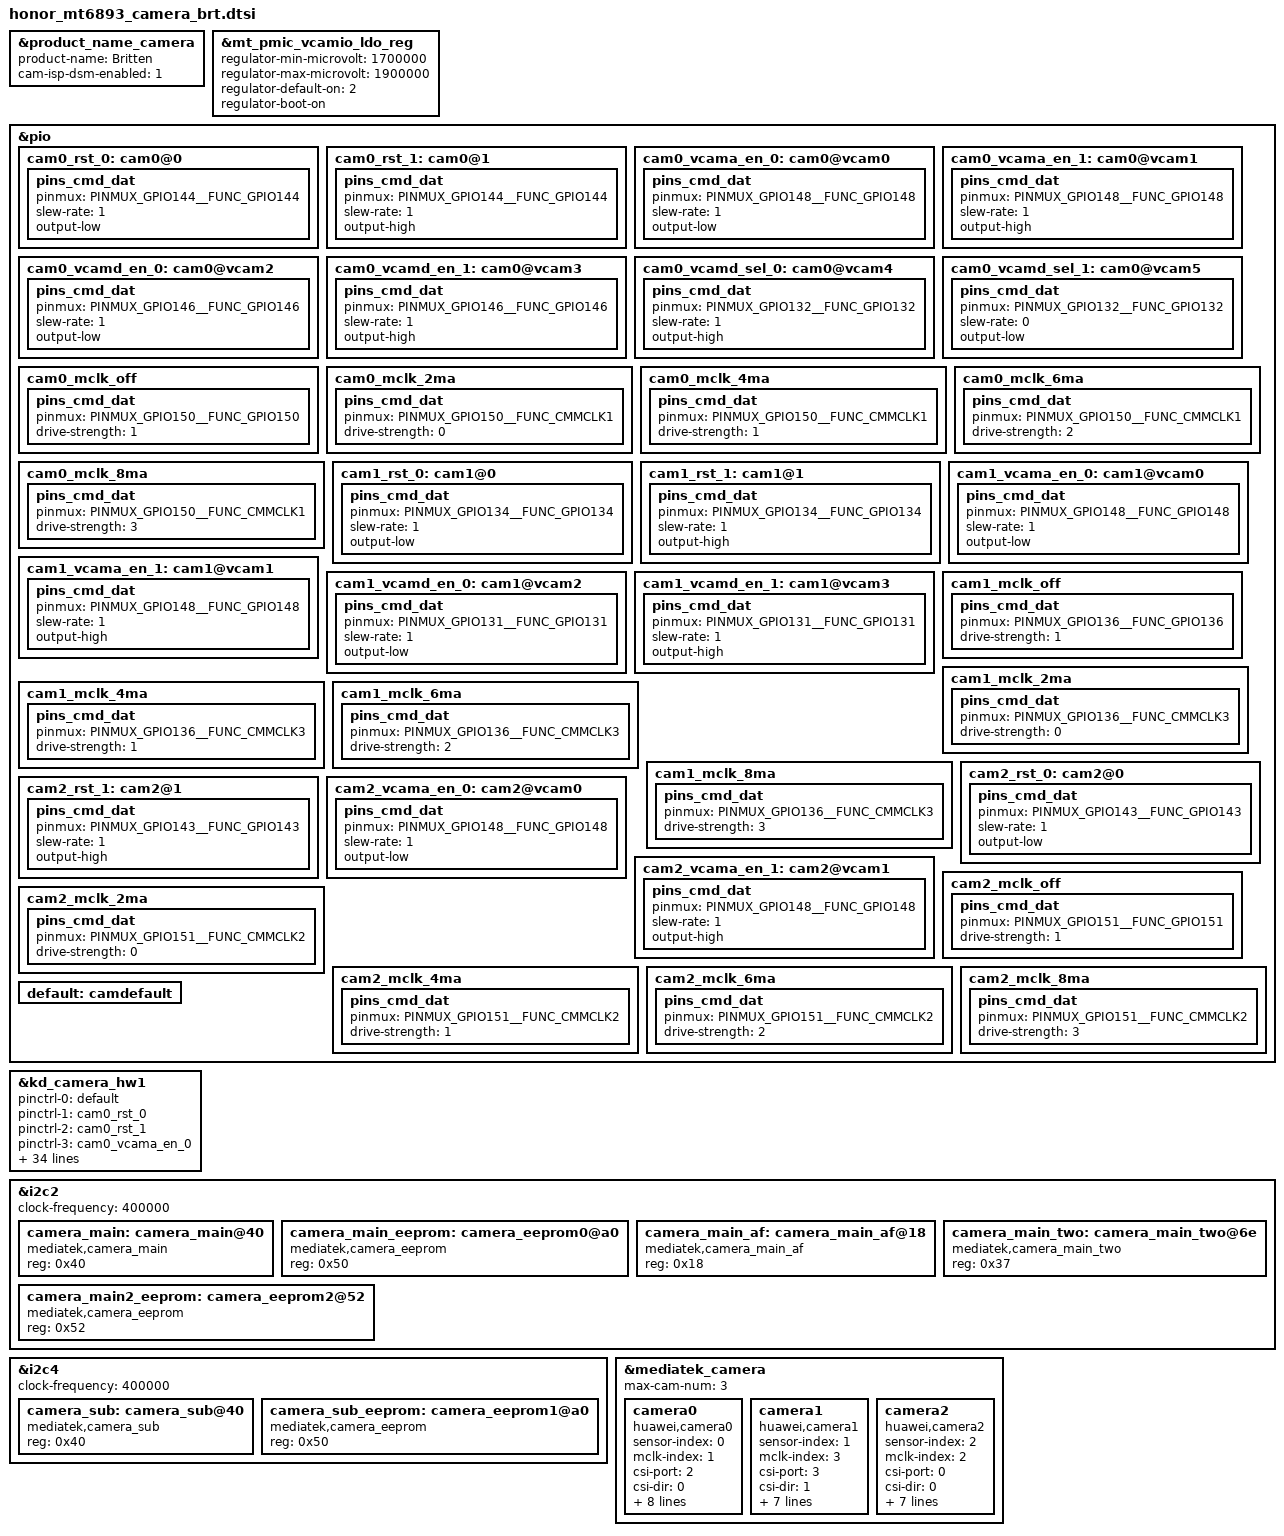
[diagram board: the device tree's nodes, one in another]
/*
 * hihonor_mt6893_camera_brt
 *
 * Copyright (c) 2021-2021 Hihonor Technologies Co., Ltd.
 *
 * hihonor_mt6893_camera_brt
 *
 * This software is licensed under the terms of the GNU General Public
 * License version 2, as published by the Free Software Foundation, and
 * may be copied, distributed, and modified under those terms.
 *
 * This program is distributed in the hope that it will be useful,
 * but WITHOUT ANY WARRANTY; without even the implied warranty of
 * MERCHANTABILITY or FITNESS FOR A PARTICULAR PURPOSE.  See the
 * GNU General Public License for more details.
 *
 */

&product_name_camera {
	product-name = "Britten";
	cam-isp-dsm-enabled = <1>;
};

&mt_pmic_vcamio_ldo_reg {
	regulator-min-microvolt = <1700000>;
	regulator-max-microvolt = <1900000>;
	regulator-default-on = <2>; /* 0:skip, 1: off, 2:on */
	regulator-boot-on;
};

/* CAMERA GPIO standardization */
&pio {
	/* Main Cam: cam0 GPIOs begin */
	cam0_rst_0: cam0@0 {
		pins_cmd_dat {
			pinmux = <PINMUX_GPIO144__FUNC_GPIO144>;
			slew-rate = <1>;
			output-low;
		};
	};
	cam0_rst_1: cam0@1 {
		pins_cmd_dat {
			pinmux = <PINMUX_GPIO144__FUNC_GPIO144>;
			slew-rate = <1>;
			output-high;
		};
	};
	cam0_vcama_en_0: cam0@vcam0 {
		pins_cmd_dat {
			pinmux = <PINMUX_GPIO148__FUNC_GPIO148>;
			slew-rate = <1>;
			output-low;
		};
	};
	cam0_vcama_en_1: cam0@vcam1 {
		pins_cmd_dat {
			pinmux = <PINMUX_GPIO148__FUNC_GPIO148>;
			slew-rate = <1>;
			output-high;
		};
	};
	cam0_vcamd_en_0: cam0@vcam2 {
		pins_cmd_dat {
			pinmux = <PINMUX_GPIO146__FUNC_GPIO146>;
			slew-rate = <1>;
			output-low;
		};
	};
	cam0_vcamd_en_1: cam0@vcam3 {
		pins_cmd_dat {
			pinmux = <PINMUX_GPIO146__FUNC_GPIO146>;
			slew-rate = <1>;
			output-high;
		};
	};
	/* sel 0, output 1.2V*/
	cam0_vcamd_sel_0: cam0@vcam4 {
		pins_cmd_dat {
			pinmux = <PINMUX_GPIO132__FUNC_GPIO132>;
			slew-rate = <1>;
			output-high;
		};
	};
	/* sel 1, output 1.1V*/
	cam0_vcamd_sel_1: cam0@vcam5 {
		pins_cmd_dat {
			pinmux = <PINMUX_GPIO132__FUNC_GPIO132>;
			slew-rate = <0>;
			output-low;
		};
	};
	cam0_mclk_off: cam0_mclk_off {
		pins_cmd_dat {
			pinmux = <PINMUX_GPIO150__FUNC_GPIO150>;
			drive-strength = <1>;
		};
	};
	cam0_mclk_2ma: cam0_mclk_2ma {
		pins_cmd_dat {
			pinmux = <PINMUX_GPIO150__FUNC_CMMCLK1>;
			drive-strength = <0>;
		};
	};
	cam0_mclk_4ma: cam0_mclk_4ma {
		pins_cmd_dat {
			pinmux = <PINMUX_GPIO150__FUNC_CMMCLK1>;
			drive-strength = <1>;
		};
	};
	cam0_mclk_6ma: cam0_mclk_6ma {
		pins_cmd_dat {
			pinmux = <PINMUX_GPIO150__FUNC_CMMCLK1>;
			drive-strength = <2>;
		};
	};
	cam0_mclk_8ma: cam0_mclk_8ma {
		pins_cmd_dat {
			pinmux = <PINMUX_GPIO150__FUNC_CMMCLK1>;
			drive-strength = <3>;
		};
	};
	/* Main Cam: cam0 GPIOs end */

	/* Sub(front) Cam: cam1 GPIOs begin */
	cam1_rst_0: cam1@0 {
		pins_cmd_dat {
			pinmux = <PINMUX_GPIO134__FUNC_GPIO134>;
			slew-rate = <1>;
			output-low;
		};
	};
	cam1_rst_1: cam1@1 {
		pins_cmd_dat {
			pinmux = <PINMUX_GPIO134__FUNC_GPIO134>;
			slew-rate = <1>;
			output-high;
		};
	};
   	cam1_vcama_en_0: cam1@vcam0 {
		pins_cmd_dat {
			pinmux = <PINMUX_GPIO148__FUNC_GPIO148>;
			slew-rate = <1>;
			output-low;
		};
	};
	cam1_vcama_en_1: cam1@vcam1 {
		pins_cmd_dat {
			pinmux = <PINMUX_GPIO148__FUNC_GPIO148>;
			slew-rate = <1>;
			output-high;
		};
	};
	cam1_vcamd_en_0: cam1@vcam2 {
		pins_cmd_dat {
			pinmux = <PINMUX_GPIO131__FUNC_GPIO131>;
			slew-rate = <1>;
			output-low;
		};
	};
	cam1_vcamd_en_1: cam1@vcam3 {
		pins_cmd_dat {
			pinmux = <PINMUX_GPIO131__FUNC_GPIO131>;
			slew-rate = <1>;
			output-high;
		};
	};
	cam1_mclk_off: cam1_mclk_off {
		pins_cmd_dat {
			pinmux = <PINMUX_GPIO136__FUNC_GPIO136>;
			drive-strength = <1>;
		};
	};
	cam1_mclk_2ma: cam1_mclk_2ma {
		pins_cmd_dat {
			pinmux = <PINMUX_GPIO136__FUNC_CMMCLK3>;
			drive-strength = <0>;
		};
	};
	cam1_mclk_4ma: cam1_mclk_4ma {
		pins_cmd_dat {
			pinmux = <PINMUX_GPIO136__FUNC_CMMCLK3>;
			drive-strength = <1>;
		};
	};
	cam1_mclk_6ma: cam1_mclk_6ma {
		pins_cmd_dat {
			pinmux = <PINMUX_GPIO136__FUNC_CMMCLK3>;
			drive-strength = <2>;
		};
	};
	cam1_mclk_8ma: cam1_mclk_8ma {
		pins_cmd_dat {
			pinmux = <PINMUX_GPIO136__FUNC_CMMCLK3>;
			drive-strength = <3>;
		};
	};
	/* Sub(front) Cam: cam1 GPIOs end */

	/* Main2(depth) Cam: cam2 GPIOs begin */
	cam2_rst_0: cam2@0 {
		pins_cmd_dat {
			pinmux = <PINMUX_GPIO143__FUNC_GPIO143>;
			slew-rate = <1>;
			output-low;
		};
	};
	cam2_rst_1: cam2@1 {
		pins_cmd_dat {
			pinmux = <PINMUX_GPIO143__FUNC_GPIO143>;
			slew-rate = <1>;
			output-high;
		};
	};
	cam2_vcama_en_0: cam2@vcam0 {
		pins_cmd_dat {
			pinmux = <PINMUX_GPIO148__FUNC_GPIO148>;
			slew-rate = <1>;
			output-low;
		};
	};
	cam2_vcama_en_1: cam2@vcam1 {
		pins_cmd_dat {
			pinmux = <PINMUX_GPIO148__FUNC_GPIO148>;
			slew-rate = <1>;
			output-high;
		};
	};
	cam2_mclk_off: cam2_mclk_off {
		pins_cmd_dat {
			pinmux = <PINMUX_GPIO151__FUNC_GPIO151>;
			drive-strength = <1>;
		};
	};
	cam2_mclk_2ma: cam2_mclk_2ma {
		pins_cmd_dat {
			pinmux = <PINMUX_GPIO151__FUNC_CMMCLK2>;
			drive-strength = <0>;
		};
	};
	cam2_mclk_4ma: cam2_mclk_4ma {
		pins_cmd_dat {
			pinmux = <PINMUX_GPIO151__FUNC_CMMCLK2>;
			drive-strength = <1>;
		};
	};
	cam2_mclk_6ma: cam2_mclk_6ma {
		pins_cmd_dat {
			pinmux = <PINMUX_GPIO151__FUNC_CMMCLK2>;
			drive-strength = <2>;
		};
	};
	cam2_mclk_8ma: cam2_mclk_8ma {
		pins_cmd_dat {
			pinmux = <PINMUX_GPIO151__FUNC_CMMCLK2>;
			drive-strength = <3>;
		};
	};
	/* Main2(depth) Cam: cam2 GPIOs end */

	default: camdefault {
	};
};

&kd_camera_hw1 {
	pinctrl-names = "default",
			/* Main Cam: Cam0 begin */
			"cam0_rst0", "cam0_rst1",
			"cam0_vcama_en_0", "cam0_vcama_en_1",
			"cam0_vcamd_en_0", "cam0_vcamd_en_1",
			"cam0_vcamd_sel_0", "cam0_vcamd_sel_1",
			"cam0_mclk_off",
			"cam0_mclk_2mA", "cam0_mclk_4mA",
			"cam0_mclk_6mA", "cam0_mclk_8mA",
			/* Main Cam: Cam0 end */

			/* Sub(front) Cam: Cam1 begin */
			"cam1_rst0", "cam1_rst1",
			"cam1_vcama_en_0", "cam1_vcama_en_1",
			"cam1_vcamd_en_0", "cam1_vcamd_en_1",
			"cam1_mclk_off",
			"cam1_mclk_2mA", "cam1_mclk_4mA",
			"cam1_mclk_6mA", "cam1_mclk_8mA",
			/* Sub(front) Cam: Cam1 end */

			/* Main2(depth) Cam: Cam2 begin */
			"cam2_rst0", "cam2_rst1",
			"cam2_vcama_en_0", "cam2_vcama_en_1",
			"cam2_mclk_off",
			"cam2_mclk_2mA", "cam2_mclk_4mA",
			"cam2_mclk_6mA", "cam2_mclk_8mA";
			/* Main2(depth) Cam: Cam2 end */

	pinctrl-0 = <&default>;
	/* Main Cam: Cam0 begin */
	pinctrl-1 = <&cam0_rst_0>;
	pinctrl-2 = <&cam0_rst_1>;
	pinctrl-3 = <&cam0_vcama_en_0>;
	pinctrl-4 = <&cam0_vcama_en_1>;
	pinctrl-5 = <&cam0_vcamd_en_0>;
	pinctrl-6 = <&cam0_vcamd_en_1>;
	pinctrl-7 = <&cam0_vcamd_sel_0>;
	pinctrl-8 = <&cam0_vcamd_sel_1>;
	pinctrl-9 = <&cam0_mclk_off>;
	pinctrl-10 = <&cam0_mclk_2ma>;
	pinctrl-11 = <&cam0_mclk_4ma>;
	pinctrl-12 = <&cam0_mclk_6ma>;
	pinctrl-13 = <&cam0_mclk_8ma>;
	/* Sub(front) Cam: Cam1 begin */
	pinctrl-14 = <&cam1_rst_0>;
	pinctrl-15 = <&cam1_rst_1>;
	pinctrl-16 = <&cam1_vcama_en_0>;
	pinctrl-17 = <&cam1_vcama_en_1>;
	pinctrl-18 = <&cam1_vcamd_en_0>;
	pinctrl-19 = <&cam1_vcamd_en_1>;
	pinctrl-20 = <&cam1_mclk_off>;
	pinctrl-21 = <&cam1_mclk_2ma>;
	pinctrl-22 = <&cam1_mclk_4ma>;
	pinctrl-23 = <&cam1_mclk_6ma>;
	pinctrl-24 = <&cam1_mclk_8ma>;
	/* Main2(depth) Cam: Cam2 begin */
	pinctrl-25 = <&cam2_rst_0>;
	pinctrl-26 = <&cam2_rst_1>;
	pinctrl-27 = <&cam0_vcama_en_0>;
	pinctrl-28 = <&cam0_vcama_en_1>;
	pinctrl-29 = <&cam2_mclk_off>;
	pinctrl-30 = <&cam2_mclk_2ma>;
	pinctrl-31 = <&cam2_mclk_4ma>;
	pinctrl-32 = <&cam2_mclk_6ma>;
	pinctrl-33 = <&cam2_mclk_8ma>;

	cam0_vcamio-supply = <&mt_pmic_vcamio_ldo_reg>;
	cam0_vcamaf-supply = <&mt_pmic_vfp_ldo_reg>;
	cam1_vcamio-supply = <&mt_pmic_vcamio_ldo_reg>;
	cam2_vcamio-supply = <&mt_pmic_vcamio_ldo_reg>;

	status = "okay";
};
/* CAMERA GPIO end */

/* CAMERA */
&i2c2 {
	clock-frequency = <400000>;
	camera_main:camera_main@40 {
		compatible = "mediatek,camera_main";
		reg = <0x40>;
		status = "okay";
	};
	camera_main_eeprom:camera_eeprom0@a0 {
		compatible = "mediatek,camera_eeprom";
		reg = <0x50>;
		status = "okay";
	};
	camera_main_af:camera_main_af@18 {
		compatible = "mediatek,camera_main_af";
		reg = <0x18>;
		status = "okay";
	};
	camera_main_two:camera_main_two@6e {
		compatible = "mediatek,camera_main_two";
		reg = <0x37>;
		status = "okay";
	};
	camera_main2_eeprom:camera_eeprom2@52 {
		compatible = "mediatek,camera_eeprom";
		reg = <0x52>;
		status = "okay";
	};
};

&i2c4 {
	clock-frequency = <400000>;
	camera_sub:camera_sub@40 {
		compatible = "mediatek,camera_sub";
		reg = <0x40>;
		status = "okay";
	};
	camera_sub_eeprom:camera_eeprom1@a0 {
		compatible = "mediatek,camera_eeprom";
		reg = <0x50>;
		status = "okay";
	};
};
/* CAMERA end */

&mediatek_camera {
	max-cam-num = "3";

	camera0 {
		compatible    = "huawei,camera0";
		sensor-index  = "0";
		mclk-index    = "1";
		csi-port      = "2";
		csi-dir       = "0";
		bit-order     = "0";
		orientation   = "270";
		sensor-hfov   = "67";
		sensor-vfov   = "49";

		i2c-dev-index = <0>;  // IMGSENSOR_I2C_DEV_0
		pin-type      =
				"mclk",
				"avdd_en",
				"dvdd_en",
				"dvdd_sel",
				"dovdd",
				"afvdd",
				"rst";
		pin-id       = <0 2 2 2 1 1 2>;
	};

	camera1 {
		compatible    = "huawei,camera1";
		sensor-index  = "1";
		mclk-index    = "3";
		csi-port      = "3";
		csi-dir       = "1";
		bit-order     = "0";
		orientation   = "270";
		sensor-hfov   = "67";
		sensor-vfov   = "40";

		i2c-dev-index = <1>;  // IMGSENSOR_I2C_DEV_1
		pin-type      =
				"mclk",
				"avdd_en",
				"dvdd_en",
				"dovdd",
				"rst";
		pin-id       = <0 2 2 1 2>;
	};

	camera2 {
		compatible    = "huawei,camera2";
		sensor-index  = "2";
		mclk-index    = "2";
		csi-port      = "0";
		csi-dir       = "0";
		bit-order     = "0";
		orientation   = "90";
		sensor-hfov   = "75";
		sensor-vfov   = "60";

		i2c-dev-index = <2>;  // IMGSENSOR_I2C_DEV_2
		pin-type      =
				"mclk",
				"avdd_en",
				"dovdd",
				"rst";
		pin-id       = <0 2 1 2>;
	};
};
